# STM32N657 register map
File version: 1.0
CPU: CM55 r0p1, little endian, no MPU, FPU, vendor SysTick, 8 interrupt priority bits
Registers are 32-bit, read-write, reset 0x0 unless marked. A register's access mark holds for its fields unless they carry their own. Offsets are from the block's base; [hi:lo] are bit positions.

## CACHEAXI — AXI cache
Base 0x480DFC00
Same registers: CACHEAXI_S 0x580DFC00
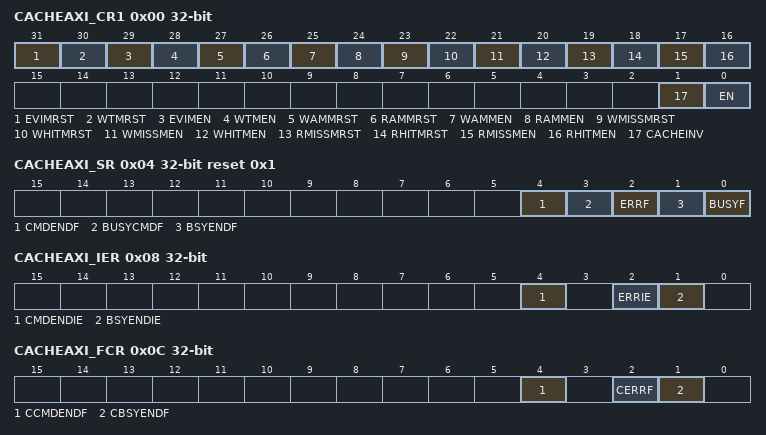
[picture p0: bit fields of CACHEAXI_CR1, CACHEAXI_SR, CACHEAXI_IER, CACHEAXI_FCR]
0x00 CACHEAXI_CR1 access per field — CACHEAXI control register 1
  [31] EVIMRST wo — eviction monitor reset
    0=no effect; 1=reset cache eviction monitor
  [30] WTMRST wo — write-through monitor reset
    0=no effect; 1=reset cache write-through monitor
  [29] EVIMEN rw — eviction monitor enable
    0=cache eviction monitor switched off. Stopping the monitor does not reset it.; 1=cache eviction monitor enabled
  [28] WTMEN rw — write-through monitor enable
    0=cache write-through monitor switched off. Stopping the monitor does not reset it.; 1=cache write-through monitor enabled
  [27] WAMMRST wo — write-allocate miss monitor reset
    0=no effect; 1=reset cache write-allocate miss monitor
  [26] RAMMRST wo — read-allocate miss monitor reset
    0=no effect; 1=reset cache read-allocate miss monitor
  [25] WAMMEN rw — write-allocate miss monitor enable
    0=cache write-allocate miss monitor switched off. Stopping the monitor does not reset it.; 1=cache write-allocate miss monitor enabled
  [24] RAMMEN rw — read-allocate miss monitor enable
    0=cache read-allocate miss monitor switched off. Stopping the monitor does not reset it.; 1=cache read-allocate miss monitor enabled
  [23] WMISSMRST wo — write-miss monitor reset
    0=no effect; 1=reset cache write-miss monitor
  [22] WHITMRST wo — write-hit monitor reset
    0=no effect; 1=reset cache write-hit monitor
  [21] WMISSMEN rw — write-miss monitor enable
    0=cache write-miss monitor switched off. Stopping the monitor does not reset it.; 1=cache write-miss monitor enabled
  [20] WHITMEN rw — write-hit monitor enable
    0=cache write-hit monitor switched off. Stopping the monitor does not reset it.; 1=cache write-hit monitor enabled
  [19] RMISSMRST wo — read-miss monitor reset
    0=no effect; 1=reset cache read-miss monitor
  [18] RHITMRST wo — read-hit monitor reset
    0=no effect; 1=reset cache read-hit monitor
  [17] RMISSMEN rw — read-miss monitor enable
    0=cache read-miss monitor switched off. Stopping the monitor does not reset it.; 1=cache read-miss monitor enabled
  [16] RHITMEN rw — read-hit monitor enable
    0=cache read-hit monitor switched off. Stopping the monitor does not reset it.; 1=cache read-hit monitor enabled
  [1] CACHEINV wo — full cache invalidation
    0=no effect; 1=invalidate entire cache (all cache lines valid bit = 0)
  [0] EN rw — enable
    0=cache mode disabled (CACHEAXI bypassed, or in SRAM mode if option supported); 1=cache mode enabled
0x04 CACHEAXI_SR ro reset 0x1 — CACHEAXI status register
  [4] CMDENDF — command end flag
    0=cache busy or in idle; 1=CACHECMD command finished
  [3] BUSYCMDF — command busy flag
    0=cache not busy on a CACHECMD command; 1=cache busy on a CACHECMD command (clean or clean-and-invalidate an address range)
  [2] ERRF — cache error flag
    0=no error; 1=an error occurred during the operation (eviction or clean operation write-back error)
  [1] BSYENDF — full invalidate busy end flag
    0=cache busy or in idle; 1=full invalidate CACHEINV operation finished
  [0] BUSYF — full invalidate busy flag
    0=cache not busy on a CACHEINV operation; 1=cache executing a full invalidate CACHEINV operation
0x08 CACHEAXI_IER — CACHEAXI interrupt enable register
  [4] CMDENDIE — interrupt enable on command end
    0=interrupt disabled on command end; 1=interrupt enabled on command end
  [2] ERRIE — interrupt enable on cache error
    0=interrupt disabled on error; 1=interrupt enabled on error
  [1] BSYENDIE — interrupt enable on busy end
    0=Interrupt disabled on busy end; 1=Interrupt enabled on busy end
0x0C CACHEAXI_FCR wo — CACHEAXI flag clear register
  [4] CCMDENDF — clear command end flag
    0=no effect; 1=clears CMDENDF flag in CACHEAXI_SR
  [2] CERRF — clear cache error flag
    0=no effect; 1=clears ERRF flag in CACHEAXI_SR
  [1] CBSYENDF — clear full invalidate busy end flag
    0=no effect; 1=clears BSYENDF flag in CACHEAXI_SR
0x10 CACHEAXI_RHMONR ro — CACHEAXI read-hit monitor register
  [31:0] RHITMON — cache read-hit monitor counter
0x14 CACHEAXI_RMMONR ro — CACHEAXI read-miss monitor register
  [31:0] RMISSMON — cache read-miss monitor counter
0x18 CACHEAXI_RAMMONR ro — CACHEAXI read-allocate miss monitor register
  [31:0] RAMMON — cache read-allocate miss monitor counter
0x1C CACHEAXI_EVIMONR ro — CACHEAXI eviction monitor register
  [31:0] EVIMON — cache eviction monitor counter
0x20 CACHEAXI_WHMONR ro — CACHEAXI write-hit monitor register
  [31:0] WHITMON — cache write-hit monitor counter
0x24 CACHEAXI_WMMONR ro — CACHEAXI write-miss monitor register
  [31:0] WMISSMON — cache write-miss monitor counter
0x28 CACHEAXI_WAMMONR ro — CACHEAXI write-allocate miss monitor register
  [31:0] WAMMON — cache write-allocate miss monitor counter
0x2C CACHEAXI_WTMONR ro — CACHEAXI write-through monitor register
  [31:0] WTMON — cache write-through monitor counter
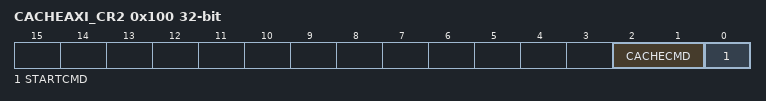
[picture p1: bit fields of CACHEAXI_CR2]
0x100 CACHEAXI_CR2 access per field — CACHEAXI control register 2
  [2:1] CACHECMD rw — cache command maintenance operation (clean or clean-and-invalidate an address range)
    0=no operation; 1=clean range; 3=clean and invalidate range
  [0] STARTCMD wo — starts maintenance range command (maintenance operation defined in CACHECMD).
    0=command operation (cache maintenance) finished; 1=start maintenance command (cache maintenance)
0x104 CACHEAXI_CMDRSADDRR — CACHEAXI command range start address register
  [31:6] CMDSTARTADDR — start address of range to which the cache maintenance command specified in CACHEAXI_CR2.CACHECMD field applies
0x108 CACHEAXI_CMDREADDRR — CACHEAXI command range end address register
  [31:6] CMDENDADDR — end address of range to which the cache maintenance command specified in CACHEAXI_CR2.CACHECMD field applies
